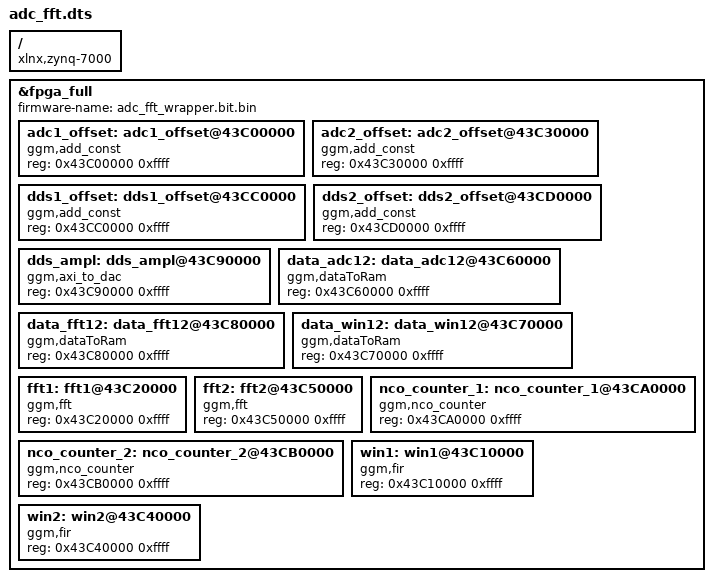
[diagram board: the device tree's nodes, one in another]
/dts-v1/;
/plugin/;

/ {
	compatible = "xlnx,zynq-7000";

	fragment0 {
		target = <&fpga_full>;
		__overlay__ {
			#address-cells = <1>;
			#size-cells = <1>;

			firmware-name = "adc_fft_wrapper.bit.bin";

			adc1_offset: adc1_offset@43C00000{
				compatible = "ggm,add_const";
				reg = <0x43C00000 0xffff>;
			};

			adc2_offset: adc2_offset@43C30000{
				compatible = "ggm,add_const";
				reg = <0x43C30000 0xffff>;
			};

			dds1_offset: dds1_offset@43CC0000{
				compatible = "ggm,add_const";
				reg = <0x43CC0000 0xffff>;
			};

			dds2_offset: dds2_offset@43CD0000{
				compatible = "ggm,add_const";
				reg = <0x43CD0000 0xffff>;
			};

			dds_ampl: dds_ampl@43C90000{
				compatible = "ggm,axi_to_dac";
				reg = <0x43C90000 0xffff>;
			};

			data_adc12: data_adc12@43C60000{
				compatible = "ggm,dataToRam";
				reg = <0x43C60000 0xffff>;
			};

			data_fft12: data_fft12@43C80000{
				compatible = "ggm,dataToRam";
				reg = <0x43C80000 0xffff>;
			};

			data_win12: data_win12@43C70000{
				compatible = "ggm,dataToRam";
				reg = <0x43C70000 0xffff>;
			};

			fft1: fft1@43C20000{
				compatible = "ggm,fft";
				reg = <0x43C20000 0xffff>;
			};

			fft2: fft2@43C50000{
				compatible = "ggm,fft";
				reg = <0x43C50000 0xffff>;
			};

			nco_counter_1: nco_counter_1@43CA0000{
				compatible = "ggm,nco_counter";
				reg = <0x43CA0000 0xffff>;
			};

			nco_counter_2: nco_counter_2@43CB0000{
				compatible = "ggm,nco_counter";
				reg = <0x43CB0000 0xffff>;
			};

			win1: win1@43C10000{
				compatible = "ggm,fir";
				reg = <0x43C10000 0xffff>;
			};

			win2: win2@43C40000{
				compatible = "ggm,fir";
				reg = <0x43C40000 0xffff>;
			};

		};
	};
};
